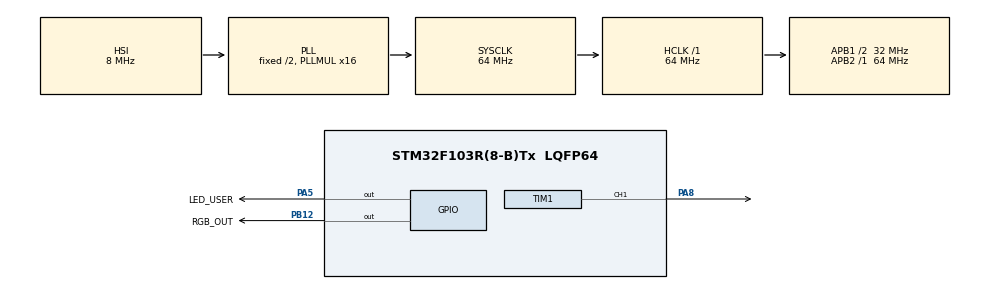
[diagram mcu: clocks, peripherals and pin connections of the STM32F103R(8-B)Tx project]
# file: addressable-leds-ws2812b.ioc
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Dma.Request0=TIM1_CH1
Dma.TIM1_CH1.0.Direction=DMA_MEMORY_TO_PERIPH
Dma.TIM1_CH1.0.Instance=DMA1_Channel2
Dma.TIM1_CH1.0.MemDataAlignment=DMA_MDATAALIGN_HALFWORD
Dma.TIM1_CH1.0.MemInc=DMA_MINC_ENABLE
Dma.TIM1_CH1.0.Mode=DMA_NORMAL
Dma.TIM1_CH1.0.PeriphDataAlignment=DMA_PDATAALIGN_HALFWORD
Dma.TIM1_CH1.0.PeriphInc=DMA_PINC_DISABLE
Dma.TIM1_CH1.0.Priority=DMA_PRIORITY_LOW
Mcu.Family=STM32F1
Mcu.Name=STM32F103R(8-B)Tx
Mcu.Package=LQFP64
NVIC.DMA1_Channel2_IRQn=true\:0\:0\:false\:false\:true\:false\:true
NVIC.PriorityGroup=NVIC_PRIORITYGROUP_4
PA13.Mode=Serial_Wire
PA13.Signal=SYS_JTMS-SWDIO
PA14.Mode=Serial_Wire
PA14.Signal=SYS_JTCK-SWCLK
PA5.GPIO_Label=LED_USER
PA5.GPIO_ModeDefaultOutputPP=GPIO_MODE_OUTPUT_OD
PA5.Signal=GPIO_Output
PA8.Signal=S_TIM1_CH1
PB12.GPIO_Label=RGB_OUT
PB12.GPIO_PuPd=GPIO_PULLDOWN
PB12.GPIO_Speed=GPIO_SPEED_FREQ_HIGH
PB12.Signal=GPIO_Output
ProjectManager.HeapSize=0x200
ProjectManager.StackSize=0x400
ProjectManager.TargetToolchain=SW4STM32
RCC.AHBFreq_Value=64000000
RCC.APB1CLKDivider=RCC_HCLK_DIV2
RCC.APB1Freq_Value=32000000
RCC.APB1TimFreq_Value=64000000
RCC.APB2Freq_Value=64000000
RCC.APB2TimFreq_Value=64000000
RCC.HCLKFreq_Value=64000000
RCC.PLLMUL=RCC_PLL_MUL16
RCC.SYSCLKFreq_VALUE=64000000
RCC.SYSCLKSource=RCC_SYSCLKSOURCE_PLLCLK
RCC.USBFreq_Value=64000000
SH.S_TIM1_CH1.0=TIM1_CH1,PWM Generation1 CH1
TIM1.Channel-PWM\ Generation1\ CH1=TIM_CHANNEL_1
TIM1.Period=80-1
VP_TIM1_VS_ClockSourceINT.Mode=Internal
board=custom

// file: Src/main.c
/* USER CODE BEGIN Header */
/**
 ******************************************************************************
 * @file           : main.c
 * @brief          : Main program body
 ******************************************************************************
 * @attention
 *
 * <h2><center>&copy; Copyright (c) 2021 STMicroelectronics.
 * All rights reserved.</center></h2>
 *
 * This software component is licensed by ST under BSD 3-Clause license,
 * the "License"; You may not use this file except in compliance with the
 * License. You may obtain a copy of the License at:
 *                        opensource.org/licenses/BSD-3-Clause
 *
 ******************************************************************************
 */
/* USER CODE END Header */

#include "main.h"
#include "dma.h"
#include "tim.h"
#include "gpio.h"

/* USER CODE BEGIN Includes */
#include "ws2812b.h"

/* USER CODE END Includes */

void SystemClock_Config(void);

int main(void) {

	/* MCU Configuration--------------------------------------------------------*/

	/* Reset of all peripherals, Initializes the Flash interface and the Systick. */
	HAL_Init();

	/* Configure the system clock */
	SystemClock_Config();

	/* Initialize all configured peripherals */
	MX_GPIO_Init();
	MX_DMA_Init();
	MX_TIM1_Init();
	/* USER CODE BEGIN 2 */
	WS2812B_InitTypeDef WS2812B_InitStruct;
	WS2812B_InitStruct.timer_channel = TIM_CHANNEL_1;
	WS2812B_InitStruct.timer = &htim1;
	WS2812B_InitStruct.led_count = 3;
	WS2812B_init(&WS2812B_InitStruct);
	/* USER CODE END 2 */

	/* Infinite loop */
	/* USER CODE BEGIN WHILE */

	uint8_t brightness = 16;
	size_t delay = 250;

	WS2812B_clear_all_now();

	while (1) {
		HAL_GPIO_TogglePin(LED_USER_GPIO_Port, LED_USER_Pin);
		WS2812B_set(0, 0, 0, brightness);
		WS2812B_set(1, 0, brightness, 0);
		WS2812B_set(2, brightness, 0, 0);
		WS2812B_send();
		HAL_Delay(delay);

		WS2812B_set(1, 0, brightness, brightness);
		WS2812B_clear_now(0);
		HAL_Delay(delay);

		WS2812B_set(2, brightness, 0, brightness);
		WS2812B_send();
		HAL_Delay(delay);

		WS2812B_clear_all_now();
		HAL_Delay(delay);
		/* USER CODE END WHILE */

	}
}

void SystemClock_Config(void) {
	RCC_OscInitTypeDef RCC_OscInitStruct = { 0 };
	RCC_ClkInitTypeDef RCC_ClkInitStruct = { 0 };

	/** Initializes the CPU, AHB and APB busses clocks
	 */
	RCC_OscInitStruct.OscillatorType = RCC_OSCILLATORTYPE_HSI;
	RCC_OscInitStruct.HSIState = RCC_HSI_ON;
	RCC_OscInitStruct.HSICalibrationValue = RCC_HSICALIBRATION_DEFAULT;
	RCC_OscInitStruct.PLL.PLLState = RCC_PLL_ON;
	RCC_OscInitStruct.PLL.PLLSource = RCC_PLLSOURCE_HSI_DIV2;
	RCC_OscInitStruct.PLL.PLLMUL = RCC_PLL_MUL16;
	if (HAL_RCC_OscConfig(&RCC_OscInitStruct) != HAL_OK) {
		Error_Handler();
	}
	/** Initializes the CPU, AHB and APB busses clocks
	 */
	RCC_ClkInitStruct.ClockType = RCC_CLOCKTYPE_HCLK | RCC_CLOCKTYPE_SYSCLK
			| RCC_CLOCKTYPE_PCLK1 | RCC_CLOCKTYPE_PCLK2;
	RCC_ClkInitStruct.SYSCLKSource = RCC_SYSCLKSOURCE_PLLCLK;
	RCC_ClkInitStruct.AHBCLKDivider = RCC_SYSCLK_DIV1;
	RCC_ClkInitStruct.APB1CLKDivider = RCC_HCLK_DIV2;
	RCC_ClkInitStruct.APB2CLKDivider = RCC_HCLK_DIV1;

	if (HAL_RCC_ClockConfig(&RCC_ClkInitStruct, FLASH_LATENCY_2) != HAL_OK) {
		Error_Handler();
	}
}

void Error_Handler(void) {
}

/************************ (C) COPYRIGHT STMicroelectronics *****END OF FILE****/
